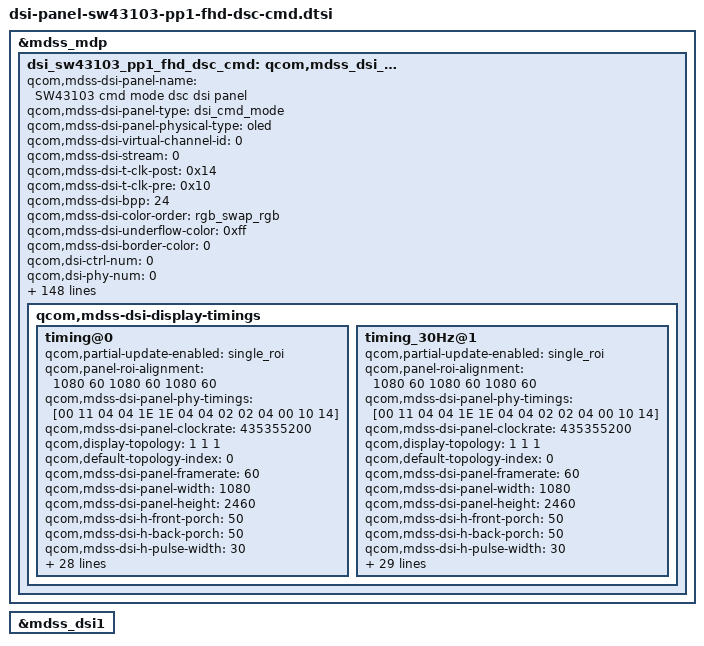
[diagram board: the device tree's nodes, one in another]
/* Copyright (c) 2014, Code Aurora Forum. All rights reserved.
 *
 * This program is free software; you can redistribute it and/or modify
 * it under the terms of the GNU General Public License version 2 and
 * only version 2 as published by the Free Software Foundation.
 *
 * This program is distributed in the hope that it will be useful,
 * but WITHOUT ANY WARRANTY; without even the implied warranty of
 * MERCHANTABILITY or FITNESS FOR A PARTICULAR PURPOSE.  See the
 * GNU General Public License for more details.
 */

&mdss_mdp {
    dsi_sw43103_pp1_fhd_dsc_cmd: qcom,mdss_dsi_sw43103_pp1_fhd_dsc_cmd {
		qcom,mdss-dsi-panel-name = "SW43103 cmd mode dsc dsi panel";
		qcom,mdss-dsi-panel-type = "dsi_cmd_mode";
		qcom,mdss-dsi-panel-physical-type = "oled";
		qcom,mdss-dsi-virtual-channel-id = <0>;
		qcom,mdss-dsi-stream = <0>;
		qcom,mdss-dsi-t-clk-post = <0x14>;
		qcom,mdss-dsi-t-clk-pre = <0x10>;
		qcom,mdss-dsi-bpp = <24>;
		qcom,mdss-dsi-color-order = "rgb_swap_rgb";
		qcom,mdss-dsi-underflow-color = <0xff>;
		qcom,mdss-dsi-border-color = <0>;
		qcom,dsi-ctrl-num = <0>;
		qcom,dsi-phy-num = <0>;
		qcom,dsi-select-clocks = "mux_byte_clk0", "mux_pixel_clk0";
		qcom,mdss-dsi-traffic-mode = "burst_mode";
		qcom,mdss-dsi-lane-map = "lane_map_0123";
		qcom,mdss-dsi-bllp-eof-power-mode;
		qcom,mdss-dsi-bllp-power-mode;
		qcom,mdss-dsi-lane-0-state;
		qcom,mdss-dsi-lane-1-state;
		qcom,mdss-dsi-lane-2-state;
		qcom,mdss-dsi-lane-3-state;
		qcom,mdss-dsi-reset-sequence = <1 10>, <0 2>, <1 10>;
		qcom,mdss-dsi-dma-trigger = "trigger_sw";
		qcom,mdss-dsi-mdp-trigger = "none";
		qcom,mdss-dsi-te-pin-select = <1>;
		qcom,panel-te-source = <0>;
		qcom,mdss-dsi-wr-mem-start = <0x2c>;
		qcom,mdss-dsi-wr-mem-continue = <0x3c>;
		qcom,mdss-dsi-te-dcs-command = <1>;
		qcom,mdss-dsi-lp11-init;
		qcom,mdss-dsi-tx-eot-append;
		qcom,ulps-enabled;
		//qcom,null-insertion-enabled;

		qcom,mdss-dsi-panel-hdr-enabled;
		qcom,mdss-dsi-panel-hdr-color-primaries = <14880 15935 32435 16555 14945 30910 7790 3415>;
		qcom,mdss-dsi-panel-peak-brightness = <5000000>;		/* max. 500nits */
		qcom,mdss-dsi-panel-blackness-level = <6134>;

		qcom,mdss-pan-physical-width-dimension = <69>;
		qcom,mdss-pan-physical-height-dimension = <158>;

		//lge,use-dim-ctrl;
		/* Brightness Map List */
		lge,blmap-daylight = <
			0
			5 5 5 5 5 5 5 5 5 5 6 7 8 10 11 12 13 14 15 17
			18 19 20 21 22 23 25 26 27 28 29 30 32 33 34 35 36 37 39 40
			41 42 43 45 46 47 48 49 51 52 53 54 55 57 58 59 60 61 63 64
			65 69 73 78 82 86 90 95 99 103 107 112 116 120 124 128 133 137 141 145
			150 154 158 163 167 171 175 180 184 189 193 197 202 206 211 215 219 224 228 233
			237 242 246 250 255 259 264 268 275 282 290 297 304 311 319 326 333 340 348 355
			362 369 376 384 391 398 405 413 420 427 434 442 449 456 464 471 479 486 494 501
			509 516 523 531 538 546 553 561 569 576 584 591 599 606 614 621 629 636 644 656
			668 680 692 704 716 728 740 752 764 776 788 800 812 824 836 848 860 872 884 896
			908 920 933 945 957 969 981 993 1005 1017 1029 1041 1053 1065 1077 1089 1101 1113 1125 1137
			1149 1161 1173 1185 1197 1209 1221 1230 1238 1247 1256 1265 1273 1282 1291 1299 1308 1317 1326 1334
			1343 1352 1361 1369 1378 1387 1395 1404 1413 1422 1430 1439 1448 1458 1467 1477 1486 1496 1505 1515
			1524 1534 1543 1553 1562 1572 1581 1591 1600 1610 1619 1629 1638 1648 1657 2047 2047 2047 2047 2047
			2047 2047 2047 2047 2047 2047 2047 2047 2047 2047 2047 2047 2047 2047 2047 2047 2047 2047 2047 2047
			2047 2047 2047 2047 2047 2047 2047 2047 2047 2047 2047 2047 2047 2047 2047 2047 2047 2047 2047 2047
			2047 2047 2047 2047 2047 2047 2047 2047 2047 2047 2047 2047 2047 2047 2047 2047 2047 2047 2047 2047
			2047 2047 2047 2047 2047 2047 2047 2047 2047 2047 2047 2047 2047 2047 2047 2047 2047 2047 2047 2047
			2047 2047 2047 2047 2047 2047 2047 2047 2047 2047 2047 2047 2047 2047 2047 2047 2047 2047 2047 2047
			2047 2047 2047 2047 2047
		>;
		lge,blmap-ve = <
			0
			5 5 5 5 5 5 5 5 5 5 6 6 7 7 8 8 9 10 10 11
			11 12 13 13 14 14 15 15 16 17 17 18 18 19 19 20 22 24 26 28
			29 31 33 35 37 39 41 43 44 46 48 50 52 54 56 58 59 61 63 65
			67 70 74 77 81 84 88 91 95 98 102 105 109 112 115 119 122 126 129 133
			136 142 148 153 150 156 161 167 173 178 184 190 196 201 207 213 218 224 230 235
			241 247 253 258 264 270 275 281 288 295 302 309 316 323 330 337 344 351 358 365
			373 380 387 394 401 408 415 422 429 436 443 450 457 464 472 480 489 497 505 513
			522 529 537 545 553 562 570 578 586 595 603 611 619 628 636 644 652 661 670 682
			695 707 720 732 744 757 769 781 794 806 819 831 843 856 868 880 893 905 918 930
			942 955 967 980 993 1005 1018 1031 1044 1057 1069 1082 1095 1108 1121 1133 1146 1159 1172 1184
			1197 1210 1223 1236 1248 1261 1274 1282 1290 1298 1306 1314 1322 1330 1338 1346 1354 1362 1370 1378
			1386 1394 1402 1410 1418 1426 1434 1442 1450 1458 1466 1474 1484 1494 1504 1514 1524 1534 1544 1554
			1564 1574 1584 1595 1605 1615 1625 1635 1645 1655 1665 1675 1685 1695 1705 1705 1705 1705 1705 1705
			1705 1705 1705 1705 1705 1705 1705 1705 1705 1705 1705 1705 1705 1705 1705 1705 1705 1705 1705 1705
			1705 1705 1705 1705 1705 1705 1705 1705 1705 1705 1705 1705 1705 1705 1705 1705 1705 1705 1705 1705
			1705 1705 1705 1705 1705 1705 1705 1705 1705 1705 1705 1705 1705 1705 1705 1705 1705 1705 1705 1705
			1705 1705 1705 1705 1705 1705 1705 1705 1705 1705 1705 1705 1705 1705 1705 1705 1705 1705 1705 1705
			1705 1705 1705 1705 1705 1705 1705 1705 1705 1705 1705 1705 1705 1705 1705 1705 1705 1705 1705 1705
			1705 1705 1705 1705 1705
		>;
		lge,blmap-ex = <
			0
			16 16 16 16 16 16 16 16 16 25 35 44 53 62 72 81 90 99 109 118
			127 136 146 155 164 173 183 192 201 210 220 229 238 247 257 266 273 281 288 295
			303 310 317 325 332 339 347 354 361 369 376 383 391 398 405 413 420 427 435 442
			449 457 464 471 479 486 493 501 508 515 523 530 537 545 552 572 592 612 632 652
			672 692 712 732 752 772 792 812 832 852 872 892 912 932 952 972 992 1009 1026 1043
			1060 1076 1093 1110 1127 1144 1161 1178 1195 1212 1228 1245 1262 1279 1296 1310 1325 1339 1353 1368
			1382 1396 1411 1425 1439 1453 1468 1482 1496 1511 1525 1539 1554 1568 1568 1568 1568 1568 1568 1568
			1589 1611 1632 1653 1674 1696 1717 1738 1759 1781 1802 1823 1844 1866 1887 1908 1929 1951 1972 1972
			1972 1972 1972 1972 1972 1972 1972 1972 1972 1972 1972 1972 1972 1972 1972 1972 1972 1972 1972 1972
			1972 1972 1972 1972 1972 1972 1972 1972 1972 1972 1972 1972 1972 1972 1972 1972 1972 1972 1972 1972
			1972 1972 1972 1972 1972 1972 1972 1972 1972 1972 1972 1972 1972 1972 1972 1972 1972 1972 1972 1972
			1972 1972 1972 1972 1972 1972 1972 1972 1972 1972 1972 1972 1972 1972 1972 1972 1972 1972 1972 1972
			1972 1972 1972 1972 1972 1972 1972 1972 1972 1972 1972 1972 1972 1972 1972
		>;
		lge,blmap-hdr-daylight = <
			0
			5 5 5 5 5 5 5 5 5 5 6 6 7 7 8 8 9 9 10 10
			11 11 12 12 13 13 14 14 15 15 16 16 17 17 18 18 22 27 31 36
			40 45 49 54 58 63 67 72 76 81 85 90 94 99 103 108 112 117 121 126
			130 133 136 139 142 145 148 150 153 156 159 162 165 168 171 174 177 180 183 185
			188 195 201 208 200 207 213 220 226 233 239 246 252 259 265 272 278 285 291 298
			304 311 317 324 330 337 343 350 358 365 373 381 388 396 404 412 419 427 435 442
			450 458 465 473 481 488 496 504 512 519 527 535 542 550 562 574 586 598 610 622
			634 642 654 666 678 690 702 714 726 738 750 762 774 786 798 810 822 834 850 860
			871 881 892 902 913 923 933 944 954 965 975 985 996 1006 1017 1027 1038 1048 1058 1069
			1079 1090 1100 1104 1108 1113 1117 1121 1125 1129 1133 1138 1142 1146 1150 1154 1158 1163 1167 1171
			1175 1179 1183 1188 1192 1196 1200 1204 1208 1212 1216 1220 1224 1228 1232 1236 1240 1244 1248 1252
			1256 1260 1264 1268 1272 1276 1280 1284 1288 1292 1296 1300 1308 1315 1323 1330 1338 1345 1353 1361
			1368 1376 1383 1391 1398 1406 1413 1421 1429 1436 1444 1451 1459 1466 1474 1481 1489 1496 1504 1511
			1519 1526 1534 1541 1549 1556 1563 1571 1578 1586 1593 1601 1608 1616 1623 1630 1638 1645 1653 1660
			1668 1675 1683 1690 1698 1705 1705 1705 1705 1705 1705 1705 1705 1705 1705 1705 1705 1705 1705 1705
			1705 1705 1705 1705 1705 1705 1705 1705 1705 1705 1705 1705 1705 1705 1705 1705 1705 1705 1705 1705
			1705 1705 1705 1705 1705 1705 1705 1705 1705 1705 1705 1705 1705 1705 1705 1705 1705 1705 1705 1705
			1705 1705 1705 1705 1705 1705 1705 1705 1705 1705 1705 1705 1705 1705 1705 1705 1705 1705 1705 1705
			1705 1705 1705 1705 1705

		>;
		lge,blmap = <
			0
			5 5 5 5 5 5 5 5 5 5 6 7 8 9 10 11 12 13 14 15
			16 17 18 18 19 20 21 22 23 24 25 26 27 28 29 30 31 32 33 34
			35 36 37 38 39 40 41 42 43 44 45 46 47 48 49 50 51 52 53 54
			55 59 62 66 69 73 77 80 84 87 91 94 98 102 105 109 112 116 120 123
			127 130 134 138 141 145 148 152 156 160 163 167 171 175 178 182 186 190 193 197
			201 205 208 212 216 220 223 227 233 240 246 252 258 265 271 277 283 290 296 302
			309 315 321 327 334 340 346 352 359 365 371 377 384 390 397 403 410 416 423 429
			436 442 448 455 461 468 475 481 488 494 501 507 514 520 527 533 540 546 553 563
			573 583 594 604 614 624 634 644 654 665 675 685 695 705 715 725 736 746 756 766
			776 786 797 807 817 827 837 847 857 868 878 888 898 908 918 928 939 949 959 969
			979 989 999 1010 1020 1030 1040 1049 1058 1067 1076 1085 1094 1103 1112 1122 1131 1140 1149 1158
			1167 1176 1185 1194 1203 1212 1221 1230 1239 1248 1257 1267 1276 1286 1296 1306 1316 1326 1335 1345
			1355 1365 1375 1385 1395 1404 1414 1424 1434 1444 1454 1463 1473 1483 1493 1495 1497 1499 1501 1503
			1505 1506 1508 1510 1512 1514 1516 1518 1520 1522 1524 1526 1528 1530 1532 1533 1535 1537 1539 1541
			1543 1545 1547 1549 1551 1553 1555 1557 1559 1560 1562 1564 1566 1568 1570 1572 1574 1576 1578 1580
			1582 1584 1586 1587 1589 1591 1593 1595 1597 1599 1601 1603 1605 1607 1609 1611 1612 1614 1616 1618
			1620 1622 1624 1626 1628 1630 1632 1634 1636 1638 1639 1641 1643 1645 1647 1649 1651 1653 1655 1657
			1659 1661 1663 1665 1666 1668 1670 1672 1674 1676 1678 1680 1682 1684 1686 1688 1690 1692 1693 1695
			1697 1699 1701 1703 1705
		>;
		lge,blmap-hdr = <
			0
			5 5 5 5 5 5 5 5 5 5 6 6 7 7 8 8 9 9 10 10
			11 11 12 12 13 13 14 14 15 15 16 16 17 17 18 18 20 21 23 24
			26 28 29 31 32 34 36 37 39 40 42 44 45 47 48 50 52 53 55 56
			58 61 64 67 70 72 75 78 81 84 87 90 93 95 98 101 104 107 110 113
			116 120 125 130 127 132 136 141 146 151 155 160 165 170 174 179 184 189 193 198
			203 208 212 217 222 227 231 236 241 247 252 258 263 269 274 279 285 290 296 301
			307 312 317 323 328 334 339 344 350 355 361 366 372 377 385 392 400 408 415 423
			430 436 444 451 459 466 474 482 489 497 505 512 520 528 535 543 551 558 568 577
			586 596 605 614 623 632 642 651 660 669 679 688 697 706 715 725 734 743 752 761
			771 780 789 801 812 824 836 847 859 870 882 894 905 917 929 940 952 963 975 987
			998 1010 1022 1033 1045 1056 1068 1079 1090 1102 1113 1124 1135 1146 1158 1169 1180 1191 1202 1214
			1225 1236 1247 1258 1270 1281 1292 1303 1314 1326 1337 1348 1364 1379 1395 1410 1426 1441 1457 1472
			1488 1503 1519 1534 1550 1565 1581 1596 1612 1627 1643 1658 1674 1689 1705 1708 1710 1713 1715 1718
			1720 1723 1725 1728 1730 1733 1735 1738 1740 1743 1745 1748 1750 1753 1755 1758 1762 1765 1768 1772
			1775 1778 1782 1785 1788 1792 1795 1798 1802 1805 1808 1812 1815 1818 1822 1825 1828 1832 1835 1838
			1842 1845 1848 1852 1855 1858 1862 1865 1868 1872 1875 1878 1882 1885 1888 1892 1895 1898 1902 1905
			1908 1912 1915 1918 1922 1925 1928 1932 1935 1938 1942 1945 1948 1952 1955 1958 1962 1965 1968 1972
			1975 1978 1982 1985 1988 1992 1995 1998 2002 2005 2008 2011 2013 2016 2019 2022 2025 2027 2030 2033
			2036 2039 2041 2044 2047
		>;

		lge,mdss-dsi-nolp-command = [
			15 01 00 00 28 00 02 53 84
			05 01 00 00 00 00 01 13
		];
		lge,mdss-dsi-nolp-command-state = "dsi_lp_mode";
		lge,mdss-dsi-lp2-command = [
			15 01 00 00 14 00 02 53 00
			05 01 00 00 00 00 01 12
		];
		lge,mdss-dsi-lp2-command-state = "dsi_lp_mode";

		lge,use-vr-lp-mode;
		lge,mdss-dsi-vr-lp-mode-on-command = [
			15 01 00 00 00 00 02 B0 A3
			39 01 00 00 00 00 08 B5 00 0B 00 3B 00 3B 10
			15 01 00 00 00 00 02 B0 CA
		];
		lge,mdss-dsi-vr-lp-mode-off-command = [
			15 01 00 00 00 00 02 B0 A3
			39 01 00 00 00 00 08 B5 00 3B 00 3B 00 3B 10
			15 01 00 00 00 00 02 B0 CA
		];
		lge,mdss-dsi-vr-lp-command-state = "dsi_lp_mode";
		lge,blmap-vr = < 0 165 >;

		lge,use-color-manager;
		lge,use-color-manager-oled;
		lge,color-manager-default-status = <1>;
		lge,mdss-dsi-color-manager-mode-table = <0 1>, <1 1>, <2 1>, <3 1>;
		lge,digital-gamma-absent;

		/* FP LHBM */
		lge,use-fp-lhbm;
		lge,use-fps-mode1-new;
		lge,mdss-dsi-fp-lhbm-ready-command = [
			15 01 00 00 00 00 02 53 A4
			39 00 00 00 00 00 03 51 05 53
			15 00 00 00 00 00 02 B0 A3
			39 00 00 00 00 00 1F B6 90 00 A1 80 F7 AA 90 00 A1 63 60 41 45 0D 94 26 BD E4 27 61 40 18 05 9C 08 A9 F8 09 A1 00
			15 01 00 00 00 00 02 B0 CA
		];
		lge,mdss-dsi-fp-lhbm-ready-command-state = "dsi_hs_mode";

		lge,mdss-dsi-fp-lhbm-exit-command = [
			15 01 00 00 00 00 02 53 84
			15 00 00 00 00 00 02 B0 A3
			39 00 00 00 00 00 1F B6 90 00 A1 80 F7 AA 71 B0 F1 63 60 41 45 0D 94 26 BD E4 27 61 40 18 05 9C 08 A9 F8 09 A1 00
			15 01 00 00 00 00 02 B0 CA
		];
		lge,mdss-dsi-fp-lhbm-exit-command-state = "dsi_hs_mode";

		lge,mdss-dsi-pre-fp-lhbm-on-command = [
			39 00 00 00 00 00 03 51 05 53
			15 00 00 00 00 00 02 B0 A3
			39 00 00 00 00 00 1F B6 90 00 A1 80 F7 AA 90 00 A1 63 60 41 45 0D 94 26 BD E4 27 61 40 18 05 9C 08 A9 F8 09 A1 00
			15 01 00 00 00 00 02 B0 CA
		];
		lge,mdss-dsi-pre-fp-lhbm-on-command-state = "dsi_hs_mode";

		lge,mdss-dsi-fp-lhbm-on-command = [
			39 01 00 00 00 00 03 51 05 53
			39 01 00 00 00 00 0B 55 08 08 72 D4 1C 61 0A 90 04 00
		];
		lge,mdss-dsi-fp-lhbm-on-command-state = "dsi_hs_mode";

		lge,mdss-dsi-fp-lhbm-off-command = [
			39 01 00 00 00 00 0B 55 08 00 72 D4 1C 61 0A 90 04 00
		];
		lge,mdss-dsi-fp-lhbm-off-command-state = "dsi_hs_mode";

		lge,mdss-dsi-post-fp-lhbm-off-command = [
			15 00 00 00 00 00 02 B0 A3
			39 00 00 00 00 00 1F B6 90 00 A1 80 F7 AA 71 B0 F1 63 60 41 45 0D 94 26 BD E4 27 61 40 18 05 9C 08 A9 F8 09 A1 00
			15 01 00 00 00 00 02 B0 CA
		];
		lge,mdss-dsi-post-fp-lhbm-off-command-state = "dsi_hs_mode";

		lge,mdss-dsi-fp-lhbm-aod-to-fps = [
			05 01 00 00 00 00 01 13 //Normal On
		];
		lge,mdss-dsi-fp-lhbm-aod-to-fps-state = "dsi_hs_mode";

		lge,mdss-dsi-fp-lhbm-fps-to-aod = [
			05 01 00 00 00 00 01 12 //AOD On
		];
		lge,mdss-dsi-fp-lhbm-fps-to-aod-state = "dsi_hs_mode";

		/* Screen Color Control */
		lge,mdss-dsi-disp-ctrl-command-1 = [
			15 01 00 00 00 00 02 B0 A1
			15 01 00 00 00 00 02 53 00
			15 01 00 00 00 00 02 B0 CA
		];
		lge,mdss-dsi-disp-ctrl-command-1-state = "dsi_hs_mode";

		lge,mdss-dsi-wb-default-command = [
			15 01 00 00 00 00 02 B0 A4
			39 01 00 00 00 00 0B B4 00 03 05 AF 03 05 AF 03 05 AF
			39 01 00 00 00 00 1C B5 00 FF 94 1F AE 37 AE 1F 94 00 FB 94 1E AD 35 AB 1C 90 00 DD 8F 16 9F 24 97 04 75
			15 01 00 00 00 00 02 B0 CA
		];
		lge,mdss-dsi-wb-default-command-state = "dsi_hs_mode";

		lge,digital-gamma-cmds-dummy = [
			15 01 00 00 00 00 02 B0 A4
			39 01 00 00 00 00 0B B4 00 03 05 AF 03 05 AF 03 05 AF
			39 01 00 00 00 00 1C B5 00 FF 94 1F AE 37 AE 1F 94 00 FB 94 1E AD 35 AB 1C 90 00 DD 8F 16 9F 24 97 04 75
			15 01 00 00 00 00 02 B0 CA
		];
		lge,digital-gamma-cmds-dummy-command = "dsi_hs_mode";

		lge,mdss-dsi-saturation-command = [
			15 01 00 00 00 00 02 B0 A4
			39 01 00 00 00 00 0D B9 35 2D 2D 37 34 35 36 36 36 2D 35 33
			15 01 00 00 00 00 02 B0 CA
		];
		lge,mdss-dsi-saturation-command-state = "dsi_hs_mode";

		lge,mdss-dsi-hue-command = [
			15 01 00 00 00 00 02 B0 A4
			39 01 00 00 00 00 0D BB 80 5A 7B 95 65 70 96 90 90 90 83 72
			15 01 00 00 00 00 02 B0 CA
		];
		lge,mdss-dsi-hue-command-state = "dsi_hs_mode";

		lge,mdss-dsi-sharpness-command = [
			15 01 00 00 00 00 02 B0 A4
			39 01 00 00 00 00 0C B2 89 1F 1F 88 24 68 22 20 04 00 00
			15 01 00 00 00 00 02 B0 CA
		];
		lge,mdss-dsi-sharpness-command-state = "dsi_hs_mode";

		lge,mdss-dsi-cm-natural = [
			15 01 00 00 00 00 02 B0 A4
			39 01 00 00 00 00 0B B4 00 03 05 AF 03 05 AF 03 05 AF
			39 01 00 00 00 00 1C B5 00 FF 94 1F AE 37 AE 1F 94 00 FB 94 1E AD 35 AB 1C 90 00 DD 8F 16 9F 24 97 04 75
			39 01 00 00 00 00 0D B7 80 80 80 80 80 80 80 80 80 80 80 80
			39 01 00 00 00 00 0D B8 80 80 80 80 80 80 80 80 80 80 80 80
			39 01 00 00 00 00 0D B9 35 2D 2D 37 34 35 36 36 36 2D 35 33
			39 01 00 00 00 00 0D BA 80 80 80 80 88 80 80 80 80 80 80 7D
			39 01 00 00 00 00 0D BB 80 5A 7B 95 65 70 96 90 90 90 83 72
			15 01 00 00 00 00 02 B0 CA
		];
		lge,mdss-dsi-cm-natural-state = "dsi_hs_mode";

		lge,mdss-dsi-cm-vivid = [
			15 01 00 00 00 00 02 B0 A4
			39 01 00 00 00 00 0B B4 00 03 05 AF 03 05 AF 03 05 AF
			39 01 00 00 00 00 1C B5 00 FF 90 22 B3 37 AE 1F 90 00 FF 8E 19 AC 34 AE 23 96 00 FF 90 1E AE 30 A6 13 88
			39 01 00 00 00 00 0D B7 80 80 80 80 80 80 80 80 80 80 80 80
			39 01 00 00 00 00 0D B8 80 80 80 80 80 80 80 80 80 80 80 80
			39 01 00 00 00 00 0D B9 43 43 43 3D 38 3E 43 43 43 43 46 46
			39 01 00 00 00 00 0D BA 80 80 80 80 80 80 80 80 80 80 80 80
			39 01 00 00 00 00 0D BB 80 80 80 80 7A 80 80 80 80 80 80 80
			15 01 00 00 00 00 02 B0 CA
		];
		lge,mdss-dsi-cm-vivid-state = "dsi_hs_mode";

		lge,mdss-dsi-cm-cinema = [
			15 01 00 00 00 00 02 B0 A4
			39 01 00 00 00 00 0B B4 00 03 05 AF 03 05 AF 03 05 AB
			39 01 00 00 00 00 1C B5 00 FF A1 26 AF 38 AF 20 95 00 EC 90 18 AF 31 A7 17 80 00 B3 8D 12 9A 14 84 F7 65
			39 01 00 00 00 00 0D B7 80 80 80 80 80 80 80 80 80 80 80 80
			39 01 00 00 00 00 0D B8 80 80 80 80 89 80 80 80 80 80 80 80
			39 01 00 00 00 00 0D B9 39 3A 36 3A 3D 38 3D 3A 3A 3A 35 35
			39 01 00 00 00 00 0D BA 80 80 80 80 88 80 80 80 80 80 7D 7D
			39 01 00 00 00 00 0D BB 6A 77 85 8B 75 70 86 85 85 80 5D 6F
			15 01 00 00 00 00 02 B0 CA
		];
		lge,mdss-dsi-cm-cinema-state = "dsi_hs_mode";

		/* Video Enahnacement */
		lge,mdss-dsi-ve-on-command = [
			15 01 00 00 00 00 02 53 84
			15 01 00 00 00 00 02 B0 A4
			39 01 00 00 00 00 0D B7 80 80 80 80 80 80 80 80 80 80 80 80
			39 01 00 00 00 00 0D B8 80 80 80 80 80 80 80 80 80 80 80 80
			39 01 00 00 00 00 0D B9 46 46 46 43 38 43 46 46 46 46 46 46
			39 01 00 00 00 00 0D BA 80 80 80 80 80 80 80 80 80 80 80 80
			39 01 00 00 00 00 0D BB 80 80 80 80 7A 80 80 80 80 80 80 80
			15 01 00 00 00 00 02 B0 CA
		];
		lge,mdss-dsi-ve-on-command-state = "dsi_hs_mode";

		lge,use-irc-ctrl;
		lge,mdss-dsi-irc-command = [
			15 01 00 00 00 00 02 B0 A5
			39 01 00 00 00 00 08 B1 60 C0 00 00 00 10 FF
			15 01 00 00 00 00 02 B0 CA
		];
		lge,mdss-dsi-irc-command-state = "dsi_hs_mode";

		lge,use-ace-ctrl;
		lge,default-ace-mode = <0>;
		lge,mdss-dsi-ace-tune-command = [
			15 01 00 00 00 00 02 B0 A4
			39 01 00 00 00 00 0C B2 89 3F 2F 88 88 88 33 20 04 00 00
			39 01 00 00 00 00 07 B3 00 80 FF 88 08 93
			15 01 00 00 00 00 02 B0 A1
			15 01 00 00 00 00 02 53 14
			39 01 00 00 00 00 02 55 28
			15 01 00 00 00 00 02 B0 CA
		];
		lge,mdss-dsi-ace-restore-command = [
			15 01 00 00 00 00 02 B0 A1
			39 01 00 00 00 00 02 55 08
			15 01 00 00 00 00 02 B0 CA
		];
		lge,mdss-dsi-ace-command-state = "dsi_hs_mode";

		/* tc Perf */
		lge,use-tc-perf;
		lge,mdss-dsi-tc-perf-on-command = [
			15 01 00 00 00 00 02 B0 A3
			39 01 00 00 00 00 1F B6 90 00 A1 90 00 A1 71 B0 F1 63 60 41 45 0D 94 26 BD E4 27 61 40 18 05 9C 08 A9 F8 09 A1 00
			15 01 00 00 00 00 02 B0 CA
		];
		lge,mdss-dsi-tc-perf-on-command-state = "dsi_hs_mode";

		lge,mdss-dsi-tc-perf-off-command = [
			15 01 00 00 00 00 02 B0 A3
			39 01 00 00 00 00 1F B6 90 00 A1 80 F7 AA 71 B0 F1 63 60 41 45 0D 94 26 BD E4 27 61 40 18 05 9C 08 A9 F8 09 A1 00
			15 01 00 00 00 00 02 B0 CA
		];
		lge,mdss-dsi-tc-perf-off-command-state = "dsi_hs_mode";

		qcom,mdss-dsi-display-timings {
			timing@0{
				qcom,partial-update-enabled = "single_roi";
				qcom,panel-roi-alignment = <1080 60 1080 60 1080 60>;
				qcom,mdss-dsi-panel-phy-timings = [00 11 04 04 1E 1E 04 04 02 02 04 00 10 14];
				qcom,mdss-dsi-panel-clockrate = <435355200>;
				qcom,display-topology = <1 1 1>;
				qcom,default-topology-index = <0>;
				qcom,mdss-dsi-panel-framerate = <60>;
				qcom,mdss-dsi-panel-width = <1080>;
				qcom,mdss-dsi-panel-height = <2460>;
				qcom,mdss-dsi-h-front-porch = <50>;
				qcom,mdss-dsi-h-back-porch = <50>;
				qcom,mdss-dsi-h-pulse-width = <30>;
				qcom,mdss-dsi-h-sync-skew = <0>;
				qcom,mdss-dsi-v-back-porch = <2>;
				qcom,mdss-dsi-v-front-porch = <4>;
				qcom,mdss-dsi-v-pulse-width = <2>;
				qcom,mdss-dsi-h-left-border = <0>;
				qcom,mdss-dsi-h-right-border = <0>;
				qcom,mdss-dsi-v-top-border = <0>;
				qcom,mdss-dsi-v-bottom-border = <0>;
				qcom,mdss-dsi-h-sync-pulse = <0>;
				//qcom,mdss-mdp-transfer-time-us = <15000>;

				qcom,mdss-dsi-on-command = [
					15 01 00 00 00 00 02 B0 A1
					39 01 00 00 00 00 05 2A 00 00 04 37
					39 01 00 00 00 00 05 2B 00 00 09 9B
					15 01 00 00 00 00 02 55 08
					39 01 00 00 00 00 05 30 00 00 09 9B
					39 01 00 00 00 00 05 31 00 00 04 37
					15 01 00 00 00 00 02 35 00
					15 01 00 00 00 00 02 B0 CA
					05 01 00 00 64 00 01 11

					15 01 00 00 00 00 02 B0 A2
					39 01 00 00 00 00 06 B7 30 0F 0F 00 10

					15 01 00 00 00 00 02 B0 A3
					39 01 00 00 00 00 05 EE 02 00 00 00
					39 01 00 00 00 00 03 BF 00 23

					15 01 00 00 00 00 02 B0 A3
					39 01 00 00 00 00 06 B3 1F 63 00 00 06

					15 01 00 00 00 00 02 B0 A5
					39 01 00 00 00 00 1E CD 10 12 01 5A 90 00 00 00 00 00 61 00 01 01 00 01 11 40 00 00 00 00 3F FF FF FF 70 FF 00 //Green Circle

					15 01 00 00 00 00 02 B0 A6
					39 01 00 00 00 00 05 FC 00 00 41 40

					15 01 00 00 00 00 02 53 84
					15 01 00 00 00 00 02 B0 A4
					39 01 00 00 00 00 0B B4 00 03 05 AF 03 05 AF 03 05 AF
					39 01 00 00 00 00 1C B5 00 FF 94 1F AE 37 AE 1F 94 00 FB 94 1E AD 35 AB 1C 90 00 DD 8F 16 9F 24 97 04 75
					39 01 00 00 00 00 0D B7 80 80 80 80 80 80 80 80 80 80 80 80
					39 01 00 00 00 00 0D B8 80 80 80 80 80 80 80 80 80 80 80 80
					39 01 00 00 00 00 0D B9 35 2D 2D 37 34 35 36 36 36 2D 35 33
					39 01 00 00 00 00 0D BA 80 80 80 80 88 80 80 80 80 80 80 7D
					39 01 00 00 00 00 0D BB 80 5A 7B 95 65 70 96 90 90 90 83 72

					15 01 00 00 00 00 02 B0 A1
					39 01 00 00 00 00 12 C1 88 C8 60 0F 4A 49 49 3A 48 4F 39 1F 4B 4B 02 02 02
					39 01 00 00 00 00 1F C3 1F 1F 27 28 28 28 28 28 28 28 1F 1F 27 28 28 28 28 28 28 28 1F 1F 27 28 28 28 28 28 28 28
					39 01 00 00 00 00 0D C4 13 13 13 13 13 13 13 13 13 13 13 13

					15 01 00 00 00 00 02 B0 CA

					05 01 00 00 14 00 01 29
				];

				qcom,mdss-dsi-off-command = [
					05 01 00 00 46 00 01 13
					05 01 00 00 00 00 01 28
					05 01 00 00 46 00 01 10
				];

				qcom,compression-mode = "dsc";
				qcom,mdss-dsc-version = <0x11>;
				qcom,mdss-dsc-scr-version = <0x1>;
				qcom,mdss-dsc-slice-height = <60>;
				qcom,mdss-dsc-slice-width = <540>;
				qcom,mdss-dsc-slice-per-pkt = <2>;
				qcom,mdss-dsc-bit-per-component = <8>;
				qcom,mdss-dsc-bit-per-pixel = <8>;
				qcom,lm-split = <540 540>;
				qcom,mdss-dsc-encoders = <2>;
				qcom,mdss-dsc-block-prediction-enable;

				qcom,mdss-dsi-on-command-state = "dsi_lp_mode";
				qcom,mdss-dsi-off-command-state = "dsi_lp_mode";

				qcom,mode-control-dsi-state = "dsi_lp_mode";
				qcom,mdss-dsi-pps-command-state = "dsi_hs_mode";
			};

			timing_30Hz@1{
				qcom,partial-update-enabled = "single_roi";
				qcom,panel-roi-alignment = <1080 60 1080 60 1080 60>;
				qcom,mdss-dsi-panel-phy-timings = [00 11 04 04 1E 1E 04 04 02 02 04 00 10 14];
				qcom,mdss-dsi-panel-clockrate = <435355200>;
				qcom,display-topology = <1 1 1>;
				qcom,default-topology-index = <0>;
				qcom,mdss-dsi-panel-framerate = <60>;
				qcom,mdss-dsi-panel-width = <1080>;
				qcom,mdss-dsi-panel-height = <2460>;
				qcom,mdss-dsi-h-front-porch = <50>;
				qcom,mdss-dsi-h-back-porch = <50>;
				qcom,mdss-dsi-h-pulse-width = <30>;
				qcom,mdss-dsi-h-sync-skew = <0>;
				qcom,mdss-dsi-v-back-porch = <2>;
				qcom,mdss-dsi-v-front-porch = <4>;
				qcom,mdss-dsi-v-pulse-width = <2>;
				qcom,mdss-dsi-h-left-border = <0>;
				qcom,mdss-dsi-h-right-border = <0>;
				qcom,mdss-dsi-v-top-border = <0>;
				qcom,mdss-dsi-v-bottom-border = <0>;
				qcom,mdss-dsi-h-sync-pulse = <0>;
				//qcom,mdss-mdp-transfer-time-us = <15000>;
				lge,mdss-dsi-panel-framerate-div = <2>;

				qcom,mdss-dsi-on-command = [
					15 01 00 00 00 00 02 B0 A1
					39 01 00 00 00 00 05 2A 00 00 04 37
					39 01 00 00 00 00 05 2B 00 00 09 9B
					15 01 00 00 00 00 02 55 08
					39 01 00 00 00 00 05 30 00 00 09 9B
					39 01 00 00 00 00 05 31 00 00 04 37
					15 01 00 00 00 00 02 35 00
					15 01 00 00 00 00 02 B0 CA
					05 01 00 00 64 00 01 11

					15 01 00 00 00 00 02 B0 A2
					39 01 00 00 00 00 06 B7 30 0F 0F 00 10

					15 01 00 00 00 00 02 B0 A3
					39 01 00 00 00 00 05 EE 02 00 00 00
					39 01 00 00 00 00 03 BF 00 23

					15 01 00 00 00 00 02 B0 A3
					39 01 00 00 00 00 06 B3 1F 63 00 00 06

					15 01 00 00 00 00 02 B0 A5
					39 01 00 00 00 00 1E CD 10 12 01 5A 90 00 00 00 00 00 61 00 01 01 00 01 11 40 00 00 00 00 3F FF FF FF 70 FF 00 //Green Circle

					15 01 00 00 00 00 02 B0 A6
					39 01 00 00 00 00 05 FC 00 00 41 40

					15 01 00 00 00 00 02 53 84
					15 01 00 00 00 00 02 B0 A4
					39 01 00 00 00 00 0B B4 00 03 05 AF 03 05 AF 03 05 AF
					39 01 00 00 00 00 1C B5 00 FF 94 1F AE 37 AE 1F 94 00 FB 94 1E AD 35 AB 1C 90 00 DD 8F 16 9F 24 97 04 75
					39 01 00 00 00 00 0D B7 80 80 80 80 80 80 80 80 80 80 80 80
					39 01 00 00 00 00 0D B8 80 80 80 80 80 80 80 80 80 80 80 80
					39 01 00 00 00 00 0D B9 35 2D 2D 37 34 35 36 36 36 2D 35 33
					39 01 00 00 00 00 0D BA 80 80 80 80 88 80 80 80 80 80 80 7D
					39 01 00 00 00 00 0D BB 80 5A 7B 95 65 70 96 90 90 90 83 72

					15 01 00 00 00 00 02 B0 A1
					39 01 00 00 00 00 12 C1 88 C8 60 0F 4A 49 49 3A 48 4F 39 1F 4B 4B 02 02 02
					39 01 00 00 00 00 1F C3 1F 1F 27 28 28 28 28 28 28 28 1F 1F 27 28 28 28 28 28 28 28 1F 1F 27 28 28 28 28 28 28 28
					39 01 00 00 00 00 0D C4 13 13 13 13 13 13 13 13 13 13 13 13

					15 01 00 00 00 00 02 B0 CA

					05 01 00 00 14 00 01 29
				];

				qcom,mdss-dsi-off-command = [
					05 01 00 00 46 00 01 13
					05 01 00 00 00 00 01 28
					05 01 00 00 46 00 01 10
				];

				qcom,compression-mode = "dsc";
				qcom,mdss-dsc-version = <0x11>;
				qcom,mdss-dsc-scr-version = <0x1>;
				qcom,mdss-dsc-slice-height = <60>;
				qcom,mdss-dsc-slice-width = <540>;
				qcom,mdss-dsc-slice-per-pkt = <2>;
				qcom,mdss-dsc-bit-per-component = <8>;
				qcom,mdss-dsc-bit-per-pixel = <8>;
				qcom,lm-split = <540 540>;
				qcom,mdss-dsc-encoders = <2>;
				qcom,mdss-dsc-block-prediction-enable;

				qcom,mdss-dsi-on-command-state = "dsi_lp_mode";
				qcom,mdss-dsi-off-command-state = "dsi_lp_mode";

				qcom,mode-control-dsi-state = "dsi_lp_mode";
				qcom,mdss-dsi-pps-command-state = "dsi_hs_mode";
			};

		};
	};
};

&mdss_dsi1 {
	status = "ok";
};
